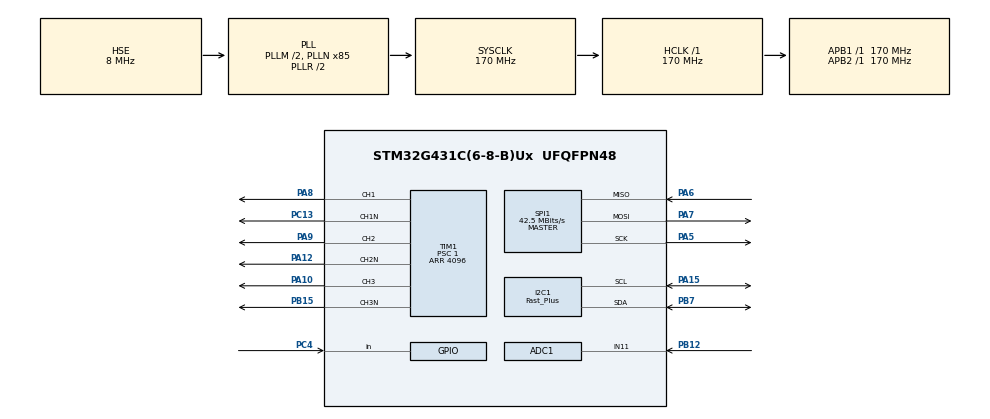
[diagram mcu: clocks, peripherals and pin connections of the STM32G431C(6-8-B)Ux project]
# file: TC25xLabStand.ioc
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ADC1.Channel-2\#ChannelRegularConversion=ADC_CHANNEL_11
ADC1.Channel-3\#ChannelRegularConversion=ADC_CHANNEL_11
ADC1.Channel-4\#ChannelRegularConversion=ADC_CHANNEL_11
ADC1.Channel-5\#ChannelRegularConversion=ADC_CHANNEL_11
ADC1.ContinuousConvMode=ENABLE
ADC1.NbrOfConversion=4
ADC1.NbrOfConversionFlag=1
ADC1.Offset-2\#ChannelRegularConversion=500
ADC1.OffsetNumber-2\#ChannelRegularConversion=ADC_OFFSET_NONE
ADC1.OffsetNumber-3\#ChannelRegularConversion=ADC_OFFSET_NONE
ADC1.OffsetNumber-4\#ChannelRegularConversion=ADC_OFFSET_NONE
ADC1.OffsetNumber-5\#ChannelRegularConversion=ADC_OFFSET_NONE
ADC1.Rank-2\#ChannelRegularConversion=1
ADC1.Rank-3\#ChannelRegularConversion=2
ADC1.Rank-4\#ChannelRegularConversion=3
ADC1.Rank-5\#ChannelRegularConversion=4
ADC1.Resolution=ADC_RESOLUTION_10B
ADC1.SamplingTime-2\#ChannelRegularConversion=ADC_SAMPLETIME_2CYCLES_5
ADC1.SamplingTime-3\#ChannelRegularConversion=ADC_SAMPLETIME_2CYCLES_5
ADC1.SamplingTime-4\#ChannelRegularConversion=ADC_SAMPLETIME_2CYCLES_5
ADC1.SamplingTime-5\#ChannelRegularConversion=ADC_SAMPLETIME_2CYCLES_5
ADC1.master=1
Dma.ADC1.3.Direction=DMA_PERIPH_TO_MEMORY
Dma.ADC1.3.EventEnable=DISABLE
Dma.ADC1.3.Instance=DMA1_Channel4
Dma.ADC1.3.MemDataAlignment=DMA_MDATAALIGN_HALFWORD
Dma.ADC1.3.MemInc=DMA_MINC_ENABLE
Dma.ADC1.3.Mode=DMA_CIRCULAR
Dma.ADC1.3.PeriphDataAlignment=DMA_PDATAALIGN_HALFWORD
Dma.ADC1.3.PeriphInc=DMA_PINC_DISABLE
Dma.ADC1.3.Polarity=HAL_DMAMUX_REQ_GEN_RISING
Dma.ADC1.3.Priority=DMA_PRIORITY_LOW
Dma.ADC1.3.RequestNumber=1
Dma.ADC1.3.SignalID=NONE
Dma.ADC1.3.SyncEnable=DISABLE
Dma.ADC1.3.SyncPolarity=HAL_DMAMUX_SYNC_NO_EVENT
Dma.ADC1.3.SyncRequestNumber=1
Dma.ADC1.3.SyncSignalID=NONE
Dma.CORDIC_READ.5.Direction=DMA_PERIPH_TO_MEMORY
Dma.CORDIC_READ.5.EventEnable=DISABLE
Dma.CORDIC_READ.5.Instance=DMA1_Channel6
Dma.CORDIC_READ.5.MemDataAlignment=DMA_MDATAALIGN_WORD
Dma.CORDIC_READ.5.MemInc=DMA_MINC_ENABLE
Dma.CORDIC_READ.5.Mode=DMA_NORMAL
Dma.CORDIC_READ.5.PeriphDataAlignment=DMA_PDATAALIGN_WORD
Dma.CORDIC_READ.5.PeriphInc=DMA_PINC_DISABLE
Dma.CORDIC_READ.5.Polarity=HAL_DMAMUX_REQ_GEN_RISING
Dma.CORDIC_READ.5.Priority=DMA_PRIORITY_LOW
Dma.CORDIC_READ.5.RequestNumber=1
Dma.CORDIC_READ.5.SignalID=NONE
Dma.CORDIC_READ.5.SyncEnable=DISABLE
Dma.CORDIC_READ.5.SyncPolarity=HAL_DMAMUX_SYNC_NO_EVENT
Dma.CORDIC_READ.5.SyncRequestNumber=1
Dma.CORDIC_READ.5.SyncSignalID=NONE
Dma.CORDIC_WRITE.6.Direction=DMA_MEMORY_TO_PERIPH
Dma.CORDIC_WRITE.6.EventEnable=DISABLE
Dma.CORDIC_WRITE.6.Instance=DMA2_Channel1
Dma.CORDIC_WRITE.6.MemDataAlignment=DMA_MDATAALIGN_WORD
Dma.CORDIC_WRITE.6.MemInc=DMA_MINC_ENABLE
Dma.CORDIC_WRITE.6.Mode=DMA_NORMAL
Dma.CORDIC_WRITE.6.PeriphDataAlignment=DMA_PDATAALIGN_WORD
Dma.CORDIC_WRITE.6.PeriphInc=DMA_PINC_DISABLE
Dma.CORDIC_WRITE.6.Polarity=HAL_DMAMUX_REQ_GEN_RISING
Dma.CORDIC_WRITE.6.Priority=DMA_PRIORITY_LOW
Dma.CORDIC_WRITE.6.RequestNumber=1
Dma.CORDIC_WRITE.6.SignalID=NONE
Dma.CORDIC_WRITE.6.SyncEnable=DISABLE
Dma.CORDIC_WRITE.6.SyncPolarity=HAL_DMAMUX_SYNC_NO_EVENT
Dma.CORDIC_WRITE.6.SyncRequestNumber=1
Dma.CORDIC_WRITE.6.SyncSignalID=NONE
Dma.I2C1_TX.4.Direction=DMA_MEMORY_TO_PERIPH
Dma.I2C1_TX.4.EventEnable=DISABLE
Dma.I2C1_TX.4.Instance=DMA1_Channel5
Dma.I2C1_TX.4.MemDataAlignment=DMA_MDATAALIGN_BYTE
Dma.I2C1_TX.4.MemInc=DMA_MINC_ENABLE
Dma.I2C1_TX.4.Mode=DMA_NORMAL
Dma.I2C1_TX.4.PeriphDataAlignment=DMA_PDATAALIGN_BYTE
Dma.I2C1_TX.4.PeriphInc=DMA_PINC_DISABLE
Dma.I2C1_TX.4.Polarity=HAL_DMAMUX_REQ_GEN_RISING
Dma.I2C1_TX.4.Priority=DMA_PRIORITY_LOW
Dma.I2C1_TX.4.RequestNumber=1
Dma.I2C1_TX.4.SignalID=NONE
Dma.I2C1_TX.4.SyncEnable=DISABLE
Dma.I2C1_TX.4.SyncPolarity=HAL_DMAMUX_SYNC_NO_EVENT
Dma.I2C1_TX.4.SyncRequestNumber=1
Dma.I2C1_TX.4.SyncSignalID=NONE
Dma.Request0=TIM1_CH1
Dma.Request1=TIM1_CH2
Dma.Request2=TIM1_CH3
Dma.Request3=ADC1
Dma.Request4=I2C1_TX
Dma.Request5=CORDIC_READ
Dma.Request6=CORDIC_WRITE
Dma.TIM1_CH1.0.Direction=DMA_MEMORY_TO_PERIPH
Dma.TIM1_CH1.0.EventEnable=DISABLE
Dma.TIM1_CH1.0.Instance=DMA1_Channel1
Dma.TIM1_CH1.0.MemDataAlignment=DMA_MDATAALIGN_WORD
Dma.TIM1_CH1.0.MemInc=DMA_MINC_ENABLE
Dma.TIM1_CH1.0.Mode=DMA_CIRCULAR
Dma.TIM1_CH1.0.PeriphDataAlignment=DMA_PDATAALIGN_WORD
Dma.TIM1_CH1.0.PeriphInc=DMA_PINC_DISABLE
Dma.TIM1_CH1.0.Polarity=HAL_DMAMUX_REQ_GEN_RISING
Dma.TIM1_CH1.0.Priority=DMA_PRIORITY_LOW
Dma.TIM1_CH1.0.RequestNumber=1
Dma.TIM1_CH1.0.SignalID=NONE
Dma.TIM1_CH1.0.SyncEnable=DISABLE
Dma.TIM1_CH1.0.SyncPolarity=HAL_DMAMUX_SYNC_NO_EVENT
Dma.TIM1_CH1.0.SyncRequestNumber=1
Dma.TIM1_CH1.0.SyncSignalID=NONE
Dma.TIM1_CH2.1.Direction=DMA_MEMORY_TO_PERIPH
Dma.TIM1_CH2.1.EventEnable=DISABLE
Dma.TIM1_CH2.1.Instance=DMA1_Channel2
Dma.TIM1_CH2.1.MemDataAlignment=DMA_MDATAALIGN_WORD
Dma.TIM1_CH2.1.MemInc=DMA_MINC_ENABLE
Dma.TIM1_CH2.1.Mode=DMA_CIRCULAR
Dma.TIM1_CH2.1.PeriphDataAlignment=DMA_PDATAALIGN_WORD
Dma.TIM1_CH2.1.PeriphInc=DMA_PINC_DISABLE
Dma.TIM1_CH2.1.Polarity=HAL_DMAMUX_REQ_GEN_RISING
Dma.TIM1_CH2.1.Priority=DMA_PRIORITY_LOW
Dma.TIM1_CH2.1.RequestNumber=1
Dma.TIM1_CH2.1.SignalID=NONE
Dma.TIM1_CH2.1.SyncEnable=DISABLE
Dma.TIM1_CH2.1.SyncPolarity=HAL_DMAMUX_SYNC_NO_EVENT
Dma.TIM1_CH2.1.SyncRequestNumber=1
Dma.TIM1_CH2.1.SyncSignalID=NONE
Dma.TIM1_CH3.2.Direction=DMA_MEMORY_TO_PERIPH
Dma.TIM1_CH3.2.EventEnable=DISABLE
Dma.TIM1_CH3.2.Instance=DMA1_Channel3
Dma.TIM1_CH3.2.MemDataAlignment=DMA_MDATAALIGN_WORD
Dma.TIM1_CH3.2.MemInc=DMA_MINC_ENABLE
Dma.TIM1_CH3.2.Mode=DMA_CIRCULAR
Dma.TIM1_CH3.2.PeriphDataAlignment=DMA_PDATAALIGN_WORD
Dma.TIM1_CH3.2.PeriphInc=DMA_PINC_DISABLE
Dma.TIM1_CH3.2.Polarity=HAL_DMAMUX_REQ_GEN_RISING
Dma.TIM1_CH3.2.Priority=DMA_PRIORITY_LOW
Dma.TIM1_CH3.2.RequestNumber=1
Dma.TIM1_CH3.2.SignalID=NONE
Dma.TIM1_CH3.2.SyncEnable=DISABLE
Dma.TIM1_CH3.2.SyncPolarity=HAL_DMAMUX_SYNC_NO_EVENT
Dma.TIM1_CH3.2.SyncRequestNumber=1
Dma.TIM1_CH3.2.SyncSignalID=NONE
I2C1.I2C_Fall_Time=50
I2C1.I2C_Rise_Time=50
I2C1.I2C_Speed_Mode=I2C_Fast_Plus
I2C1.Timing=0x10801030
Mcu.Family=STM32G4
Mcu.Name=STM32G431C(6-8-B)Ux
Mcu.Package=UFQFPN48
NVIC.ADC1_2_IRQn=true\:14\:0\:true\:false\:true\:true\:true\:true
NVIC.DMA1_Channel1_IRQn=true\:0\:0\:false\:false\:true\:false\:true\:true
NVIC.DMA1_Channel2_IRQn=true\:0\:0\:false\:false\:true\:false\:true\:true
NVIC.DMA1_Channel3_IRQn=true\:0\:0\:false\:false\:true\:false\:true\:true
NVIC.DMA1_Channel4_IRQn=true\:0\:0\:false\:false\:true\:false\:true\:true
NVIC.DMA1_Channel5_IRQn=true\:0\:0\:false\:false\:true\:false\:true\:true
NVIC.DMA1_Channel6_IRQn=true\:0\:0\:false\:false\:true\:false\:true\:true
NVIC.DMA2_Channel1_IRQn=true\:0\:0\:false\:false\:true\:false\:true\:true
NVIC.I2C1_ER_IRQn=true\:0\:0\:false\:false\:true\:true\:true\:true
NVIC.I2C1_EV_IRQn=true\:0\:0\:false\:false\:true\:true\:true\:true
NVIC.PriorityGroup=NVIC_PRIORITYGROUP_4
PA10.GPIO_Speed=GPIO_SPEED_FREQ_VERY_HIGH
PA10.Signal=S_TIM1_CH3
PA12.GPIO_Speed=GPIO_SPEED_FREQ_VERY_HIGH
PA12.Mode=PWM Generation2 CH2 CH2N
PA12.Signal=TIM1_CH2N
PA13.Mode=Serial_Wire
PA13.Signal=SYS_JTMS-SWDIO
PA14.Mode=Serial_Wire
PA14.Signal=SYS_JTCK-SWCLK
PA15.GPIO_Pu=GPIO_PULLUP
PA15.GPIO_Speed=GPIO_SPEED_FREQ_VERY_HIGH
PA15.Mode=I2C
PA15.Signal=I2C1_SCL
PA5.Mode=Full_Duplex_Master
PA5.Signal=SPI1_SCK
PA6.Mode=Full_Duplex_Master
PA6.Signal=SPI1_MISO
PA7.Mode=Full_Duplex_Master
PA7.Signal=SPI1_MOSI
PA8.GPIO_Speed=GPIO_SPEED_FREQ_VERY_HIGH
PA8.Signal=S_TIM1_CH1
PA9.GPIO_Speed=GPIO_SPEED_FREQ_VERY_HIGH
PA9.Signal=S_TIM1_CH2
PB12.Mode=IN11-Single-Ended
PB12.Signal=ADC1_IN11
PB15.GPIO_Speed=GPIO_SPEED_FREQ_VERY_HIGH
PB15.Mode=PWM Generation3 CH3 CH3N
PB15.Signal=TIM1_CH3N
PB7.GPIO_Pu=GPIO_PULLUP
PB7.GPIO_Speed=GPIO_SPEED_FREQ_VERY_HIGH
PB7.Mode=I2C
PB7.Signal=I2C1_SDA
PC13.GPIO_PuPd=GPIO_NOPULL
PC13.GPIO_Speed=GPIO_SPEED_FREQ_LOW
PC13.Mode=PWM Generation1 CH1 CH1N
PC13.Signal=TIM1_CH1N
PC4.Signal=GPIO_Input
PF0-OSC_IN.Mode=HSE-External-Oscillator
PF0-OSC_IN.Signal=RCC_OSC_IN
PF1-OSC_OUT.Mode=HSE-External-Oscillator
PF1-OSC_OUT.Signal=RCC_OSC_OUT
ProjectManager.HeapSize=0x200
ProjectManager.StackSize=0x400
ProjectManager.TargetToolchain=STM32CubeIDE
RCC.ADC12Freq_Value=170000000
RCC.AHBFreq_Value=170000000
RCC.APB1Freq_Value=170000000
RCC.APB1TimFreq_Value=170000000
RCC.APB2Freq_Value=170000000
RCC.APB2TimFreq_Value=170000000
RCC.CortexFreq_Value=170000000
RCC.EXTERNAL_CLOCK_VALUE=12288000
RCC.HCLKFreq_Value=170000000
RCC.HSE_VALUE=8000000
RCC.HSI48_VALUE=48000000
RCC.HSI_VALUE=16000000
RCC.LSE_VALUE=32768
RCC.PLLM=RCC_PLLM_DIV2
RCC.PLLN=85
RCC.PLLSourceVirtual=RCC_PLLSOURCE_HSE
RCC.SYSCLKFreq_VALUE=170000000
RCC.SYSCLKSource=RCC_SYSCLKSOURCE_PLLCLK
RCC.USBFreq_Value=170000000
RCC.VCOOutputFreq_Value=340000000
SH.S_TIM1_CH1.0=TIM1_CH1,PWM Generation1 CH1 CH1N
SH.S_TIM1_CH2.0=TIM1_CH2,PWM Generation2 CH2 CH2N
SH.S_TIM1_CH3.0=TIM1_CH3,PWM Generation3 CH3 CH3N
SPI1.BaudRatePrescaler=SPI_BAUDRATEPRESCALER_4
SPI1.CalculateBaudRate=42.5 MBits/s
SPI1.Direction=SPI_DIRECTION_2LINES
SPI1.Mode=SPI_MODE_MASTER
SPI1.VirtualType=VM_MASTER
TIM1.Channel-PWM\ Generation1\ CH1\ CH1N=TIM_CHANNEL_1
TIM1.Channel-PWM\ Generation2\ CH2\ CH2N=TIM_CHANNEL_2
TIM1.Channel-PWM\ Generation3\ CH3\ CH3N=TIM_CHANNEL_3
TIM1.DeadTime=36
TIM1.OCFastMode_PWM-PWM\ Generation1\ CH1\ CH1N=TIM_OCFAST_ENABLE
TIM1.OCFastMode_PWM-PWM\ Generation2\ CH2\ CH2N=TIM_OCFAST_ENABLE
TIM1.OCFastMode_PWM-PWM\ Generation3\ CH3\ CH3N=TIM_OCFAST_ENABLE
TIM1.PeriodNoDither=4096
TIM1.Prescaler=1
VP_CORDIC_VS_CORDIC.Mode=CORDIC_Activate
VP_SYS_VS_DBSignals.Mode=DisableDeadBatterySignals
VP_TIM1_VS_ClockSourceINT.Mode=Internal
board=custom

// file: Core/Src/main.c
/* USER CODE BEGIN Header */
/* USER CODE END Header */
#include "main.h"
#include "ADC_handler.h"

//ADC_HandleTypeDef hadc1;
//DMA_HandleTypeDef hdma_adc1;

CORDIC_HandleTypeDef hcordic;
DMA_HandleTypeDef hdma_cordic_read;
DMA_HandleTypeDef hdma_cordic_write;

I2C_HandleTypeDef hi2c1;
DMA_HandleTypeDef hdma_i2c1_tx;

SPI_HandleTypeDef hspi1;

TIM_HandleTypeDef htim1;
DMA_HandleTypeDef hdma_tim1_ch1;
DMA_HandleTypeDef hdma_tim1_ch2;
DMA_HandleTypeDef hdma_tim1_ch3;

/* USER CODE BEGIN PV */
CORDIC_ConfigTypeDef CORDIC_Sine;

/* USER CODE END PV */

void SystemClock_Config(void);
static void MX_GPIO_Init(void);
static void MX_DMA_Init(void);
static void MX_I2C1_Init(void);
static void MX_SPI1_Init(void);
static void MX_TIM1_Init(void);
static void MX_ADC1_Init(void);
static void MX_CORDIC_Init(void);

int main(void)
{

  /* MCU Configuration--------------------------------------------------------*/

  /* Reset of all peripherals, Initializes the Flash interface and the Systick. */
  HAL_Init();

  /* Configure the system clock */
  SystemClock_Config();

  /* Initialize all configured peripherals */
  MX_GPIO_Init();
  MX_DMA_Init();
  MX_I2C1_Init();
  MX_SPI1_Init();
  MX_TIM1_Init();
  MX_ADC1_Init();
  MX_CORDIC_Init();
  /* USER CODE BEGIN 2 */
  CORDIC_Sine.Function = CORDIC_FUNCTION_SINE;
  CORDIC_Sine.Precision = CORDIC_PRECISION_6CYCLES;
  CORDIC_Sine.Scale = CORDIC_SCALE_0;
  CORDIC_Sine.NbWrite = CORDIC_NBWRITE_1;
  CORDIC_Sine.NbRead = CORDIC_NBREAD_1;
  CORDIC_Sine.InSize = CORDIC_INSIZE_32BITS;
  CORDIC_Sine.OutSize = CORDIC_OUTSIZE_32BITS;
  if(HAL_CORDIC_Configure(&hcordic, &CORDIC_Sine) != HAL_OK){
	  Error_Handler();
  }

  /* USER CODE END 2 */

  /* Infinite loop */

}

void SystemClock_Config(void)
{
  RCC_OscInitTypeDef RCC_OscInitStruct = {0};
  RCC_ClkInitTypeDef RCC_ClkInitStruct = {0};

  /** Configure the main internal regulator output voltage
  */
  HAL_PWREx_ControlVoltageScaling(PWR_REGULATOR_VOLTAGE_SCALE1_BOOST);

  /** Initializes the RCC Oscillators according to the specified parameters
  * in the RCC_OscInitTypeDef structure.
  */
  RCC_OscInitStruct.OscillatorType = RCC_OSCILLATORTYPE_HSE;
  RCC_OscInitStruct.HSEState = RCC_HSE_ON;
  RCC_OscInitStruct.PLL.PLLState = RCC_PLL_ON;
  RCC_OscInitStruct.PLL.PLLSource = RCC_PLLSOURCE_HSE;
  RCC_OscInitStruct.PLL.PLLM = RCC_PLLM_DIV2;
  RCC_OscInitStruct.PLL.PLLN = 85;
  RCC_OscInitStruct.PLL.PLLP = RCC_PLLP_DIV2;
  RCC_OscInitStruct.PLL.PLLQ = RCC_PLLQ_DIV2;
  RCC_OscInitStruct.PLL.PLLR = RCC_PLLR_DIV2;
  if (HAL_RCC_OscConfig(&RCC_OscInitStruct) != HAL_OK)
  {
    Error_Handler();
  }

  /** Initializes the CPU, AHB and APB buses clocks
  */
  RCC_ClkInitStruct.ClockType = RCC_CLOCKTYPE_HCLK|RCC_CLOCKTYPE_SYSCLK
                              |RCC_CLOCKTYPE_PCLK1|RCC_CLOCKTYPE_PCLK2;
  RCC_ClkInitStruct.SYSCLKSource = RCC_SYSCLKSOURCE_PLLCLK;
  RCC_ClkInitStruct.AHBCLKDivider = RCC_SYSCLK_DIV1;
  RCC_ClkInitStruct.APB1CLKDivider = RCC_HCLK_DIV1;
  RCC_ClkInitStruct.APB2CLKDivider = RCC_HCLK_DIV1;

  if (HAL_RCC_ClockConfig(&RCC_ClkInitStruct, FLASH_LATENCY_4) != HAL_OK)
  {
    Error_Handler();
  }
}

static void MX_ADC1_Init(void)
{

  ADC_MultiModeTypeDef multimode = {0};
  ADC_ChannelConfTypeDef sConfig = {0};

  /** Common config
  */
  hadc1.Instance = ADC1;
  hadc1.Init.ClockPrescaler = ADC_CLOCK_SYNC_PCLK_DIV4;
  hadc1.Init.Resolution = ADC_RESOLUTION_10B;
  hadc1.Init.DataAlign = ADC_DATAALIGN_RIGHT;
  hadc1.Init.GainCompensation = 0;
  hadc1.Init.ScanConvMode = ADC_SCAN_ENABLE;
  hadc1.Init.EOCSelection = ADC_EOC_SINGLE_CONV;
  hadc1.Init.LowPowerAutoWait = DISABLE;
  hadc1.Init.ContinuousConvMode = ENABLE;
  hadc1.Init.NbrOfConversion = 4;
  hadc1.Init.DiscontinuousConvMode = DISABLE;
  hadc1.Init.ExternalTrigConv = ADC_SOFTWARE_START;
  hadc1.Init.ExternalTrigConvEdge = ADC_EXTERNALTRIGCONVEDGE_NONE;
  hadc1.Init.DMAContinuousRequests = DISABLE;
  hadc1.Init.Overrun = ADC_OVR_DATA_PRESERVED;
  hadc1.Init.OversamplingMode = DISABLE;
  if (HAL_ADC_Init(&hadc1) != HAL_OK)
  {
    Error_Handler();
  }

  /** Configure the ADC multi-mode
  */
  multimode.Mode = ADC_MODE_INDEPENDENT;
  if (HAL_ADCEx_MultiModeConfigChannel(&hadc1, &multimode) != HAL_OK)
  {
    Error_Handler();
  }

  /** Configure Regular Channel
  */
  sConfig.Channel = ADC_CHANNEL_11;
  sConfig.Rank = ADC_REGULAR_RANK_1;
  sConfig.SamplingTime = ADC_SAMPLETIME_2CYCLES_5;
  sConfig.SingleDiff = ADC_SINGLE_ENDED;
  sConfig.OffsetNumber = ADC_OFFSET_NONE;
  sConfig.Offset = 500;
  if (HAL_ADC_ConfigChannel(&hadc1, &sConfig) != HAL_OK)
  {
    Error_Handler();
  }

  /** Configure Regular Channel
  */
  sConfig.Rank = ADC_REGULAR_RANK_2;
  sConfig.Offset = 0;
  if (HAL_ADC_ConfigChannel(&hadc1, &sConfig) != HAL_OK)
  {
    Error_Handler();
  }

  /** Configure Regular Channel
  */
  sConfig.Rank = ADC_REGULAR_RANK_3;
  if (HAL_ADC_ConfigChannel(&hadc1, &sConfig) != HAL_OK)
  {
    Error_Handler();
  }

  /** Configure Regular Channel
  */
  sConfig.Rank = ADC_REGULAR_RANK_4;
  if (HAL_ADC_ConfigChannel(&hadc1, &sConfig) != HAL_OK)
  {
    Error_Handler();
  }

}

static void MX_CORDIC_Init(void)
{

  hcordic.Instance = CORDIC;
  if (HAL_CORDIC_Init(&hcordic) != HAL_OK)
  {
    Error_Handler();
  }

}

static void MX_I2C1_Init(void)
{

  hi2c1.Instance = I2C1;
  hi2c1.Init.Timing = 0x10801030;
  hi2c1.Init.OwnAddress1 = 0;
  hi2c1.Init.AddressingMode = I2C_ADDRESSINGMODE_7BIT;
  hi2c1.Init.DualAddressMode = I2C_DUALADDRESS_DISABLE;
  hi2c1.Init.OwnAddress2 = 0;
  hi2c1.Init.OwnAddress2Masks = I2C_OA2_NOMASK;
  hi2c1.Init.GeneralCallMode = I2C_GENERALCALL_DISABLE;
  hi2c1.Init.NoStretchMode = I2C_NOSTRETCH_DISABLE;
  if (HAL_I2C_Init(&hi2c1) != HAL_OK)
  {
    Error_Handler();
  }

  /** Configure Analogue filter
  */
  if (HAL_I2CEx_ConfigAnalogFilter(&hi2c1, I2C_ANALOGFILTER_ENABLE) != HAL_OK)
  {
    Error_Handler();
  }

  /** Configure Digital filter
  */
  if (HAL_I2CEx_ConfigDigitalFilter(&hi2c1, 0) != HAL_OK)
  {
    Error_Handler();
  }

  /** I2C Fast mode Plus enable
  */
  HAL_I2CEx_EnableFastModePlus(I2C_FASTMODEPLUS_I2C1);

}

static void MX_SPI1_Init(void)
{

  /* SPI1 parameter configuration*/
  hspi1.Instance = SPI1;
  hspi1.Init.Mode = SPI_MODE_MASTER;
  hspi1.Init.Direction = SPI_DIRECTION_2LINES;
  hspi1.Init.DataSize = SPI_DATASIZE_4BIT;
  hspi1.Init.CLKPolarity = SPI_POLARITY_LOW;
  hspi1.Init.CLKPhase = SPI_PHASE_1EDGE;
  hspi1.Init.NSS = SPI_NSS_SOFT;
  hspi1.Init.BaudRatePrescaler = SPI_BAUDRATEPRESCALER_4;
  hspi1.Init.FirstBit = SPI_FIRSTBIT_MSB;
  hspi1.Init.TIMode = SPI_TIMODE_DISABLE;
  hspi1.Init.CRCCalculation = SPI_CRCCALCULATION_DISABLE;
  hspi1.Init.CRCPolynomial = 7;
  hspi1.Init.CRCLength = SPI_CRC_LENGTH_DATASIZE;
  hspi1.Init.NSSPMode = SPI_NSS_PULSE_ENABLE;
  if (HAL_SPI_Init(&hspi1) != HAL_OK)
  {
    Error_Handler();
  }

}

static void MX_TIM1_Init(void)
{

  TIM_ClockConfigTypeDef sClockSourceConfig = {0};
  TIM_MasterConfigTypeDef sMasterConfig = {0};
  TIM_OC_InitTypeDef sConfigOC = {0};
  TIM_BreakDeadTimeConfigTypeDef sBreakDeadTimeConfig = {0};

  htim1.Instance = TIM1;
  htim1.Init.Prescaler = 1;
  htim1.Init.CounterMode = TIM_COUNTERMODE_UP;
  htim1.Init.Period = 4096;
  htim1.Init.ClockDivision = TIM_CLOCKDIVISION_DIV1;
  htim1.Init.RepetitionCounter = 0;
  htim1.Init.AutoReloadPreload = TIM_AUTORELOAD_PRELOAD_DISABLE;
  if (HAL_TIM_Base_Init(&htim1) != HAL_OK)
  {
    Error_Handler();
  }
  sClockSourceConfig.ClockSource = TIM_CLOCKSOURCE_INTERNAL;
  if (HAL_TIM_ConfigClockSource(&htim1, &sClockSourceConfig) != HAL_OK)
  {
    Error_Handler();
  }
  if (HAL_TIM_PWM_Init(&htim1) != HAL_OK)
  {
    Error_Handler();
  }
  sMasterConfig.MasterOutputTrigger = TIM_TRGO_RESET;
  sMasterConfig.MasterOutputTrigger2 = TIM_TRGO2_RESET;
  sMasterConfig.MasterSlaveMode = TIM_MASTERSLAVEMODE_DISABLE;
  if (HAL_TIMEx_MasterConfigSynchronization(&htim1, &sMasterConfig) != HAL_OK)
  {
    Error_Handler();
  }
  sConfigOC.OCMode = TIM_OCMODE_PWM1;
  sConfigOC.Pulse = 0;
  sConfigOC.OCPolarity = TIM_OCPOLARITY_HIGH;
  sConfigOC.OCNPolarity = TIM_OCNPOLARITY_HIGH;
  sConfigOC.OCFastMode = TIM_OCFAST_ENABLE;
  sConfigOC.OCIdleState = TIM_OCIDLESTATE_RESET;
  sConfigOC.OCNIdleState = TIM_OCNIDLESTATE_RESET;
  if (HAL_TIM_PWM_ConfigChannel(&htim1, &sConfigOC, TIM_CHANNEL_1) != HAL_OK)
  {
    Error_Handler();
  }
  if (HAL_TIM_PWM_ConfigChannel(&htim1, &sConfigOC, TIM_CHANNEL_2) != HAL_OK)
  {
    Error_Handler();
  }
  if (HAL_TIM_PWM_ConfigChannel(&htim1, &sConfigOC, TIM_CHANNEL_3) != HAL_OK)
  {
    Error_Handler();
  }
  sBreakDeadTimeConfig.OffStateRunMode = TIM_OSSR_DISABLE;
  sBreakDeadTimeConfig.OffStateIDLEMode = TIM_OSSI_DISABLE;
  sBreakDeadTimeConfig.LockLevel = TIM_LOCKLEVEL_OFF;
  sBreakDeadTimeConfig.DeadTime = 36;
  sBreakDeadTimeConfig.BreakState = TIM_BREAK_DISABLE;
  sBreakDeadTimeConfig.BreakPolarity = TIM_BREAKPOLARITY_HIGH;
  sBreakDeadTimeConfig.BreakFilter = 0;
  sBreakDeadTimeConfig.BreakAFMode = TIM_BREAK_AFMODE_INPUT;
  sBreakDeadTimeConfig.Break2State = TIM_BREAK2_DISABLE;
  sBreakDeadTimeConfig.Break2Polarity = TIM_BREAK2POLARITY_HIGH;
  sBreakDeadTimeConfig.Break2Filter = 0;
  sBreakDeadTimeConfig.Break2AFMode = TIM_BREAK_AFMODE_INPUT;
  sBreakDeadTimeConfig.AutomaticOutput = TIM_AUTOMATICOUTPUT_DISABLE;
  if (HAL_TIMEx_ConfigBreakDeadTime(&htim1, &sBreakDeadTimeConfig) != HAL_OK)
  {
    Error_Handler();
  }
  HAL_TIM_MspPostInit(&htim1);

}

static void MX_DMA_Init(void)
{

  /* DMA controller clock enable */
  __HAL_RCC_DMAMUX1_CLK_ENABLE();
  __HAL_RCC_DMA1_CLK_ENABLE();
  __HAL_RCC_DMA2_CLK_ENABLE();

  /* DMA interrupt init */
  /* DMA1_Channel1_IRQn interrupt configuration */
  HAL_NVIC_SetPriority(DMA1_Channel1_IRQn, 0, 0);
  HAL_NVIC_EnableIRQ(DMA1_Channel1_IRQn);
  /* DMA1_Channel2_IRQn interrupt configuration */
  HAL_NVIC_SetPriority(DMA1_Channel2_IRQn, 0, 0);
  HAL_NVIC_EnableIRQ(DMA1_Channel2_IRQn);
  /* DMA1_Channel3_IRQn interrupt configuration */
  HAL_NVIC_SetPriority(DMA1_Channel3_IRQn, 0, 0);
  HAL_NVIC_EnableIRQ(DMA1_Channel3_IRQn);
  /* DMA1_Channel4_IRQn interrupt configuration */
  HAL_NVIC_SetPriority(DMA1_Channel4_IRQn, 0, 0);
  HAL_NVIC_EnableIRQ(DMA1_Channel4_IRQn);
  /* DMA1_Channel5_IRQn interrupt configuration */
  HAL_NVIC_SetPriority(DMA1_Channel5_IRQn, 0, 0);
  HAL_NVIC_EnableIRQ(DMA1_Channel5_IRQn);
  /* DMA1_Channel6_IRQn interrupt configuration */
  HAL_NVIC_SetPriority(DMA1_Channel6_IRQn, 0, 0);
  HAL_NVIC_EnableIRQ(DMA1_Channel6_IRQn);
  /* DMA2_Channel1_IRQn interrupt configuration */
  HAL_NVIC_SetPriority(DMA2_Channel1_IRQn, 0, 0);
  HAL_NVIC_EnableIRQ(DMA2_Channel1_IRQn);

}

static void MX_GPIO_Init(void)
{
  GPIO_InitTypeDef GPIO_InitStruct = {0};

  /* GPIO Ports Clock Enable */
  __HAL_RCC_GPIOC_CLK_ENABLE();
  __HAL_RCC_GPIOF_CLK_ENABLE();
  __HAL_RCC_GPIOA_CLK_ENABLE();
  __HAL_RCC_GPIOB_CLK_ENABLE();

  /*Configure GPIO pin : PC4 */
  GPIO_InitStruct.Pin = GPIO_PIN_4;
  GPIO_InitStruct.Mode = GPIO_MODE_INPUT;
  GPIO_InitStruct.Pull = GPIO_NOPULL;
  HAL_GPIO_Init(GPIOC, &GPIO_InitStruct);

}

void Error_Handler(void)
{
}
